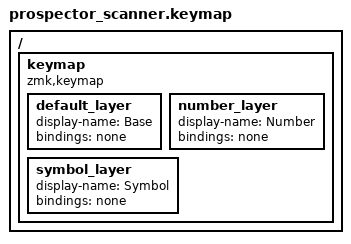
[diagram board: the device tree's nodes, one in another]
/*
 * Copyright (c) 2024 The ZMK Contributors
 *
 * SPDX-License-Identifier: MIT
 */

#include <behaviors.dtsi>
#include <dt-bindings/zmk/keys.h>
#include <dt-bindings/zmk/bt.h>
#include <dt-bindings/zmk/outputs.h>

/ {
    keymap {
        compatible = "zmk,keymap";

        // Default layer - scanner has no physical keys
        default_layer {
            display-name = "Base";
            bindings = <&none>;
        };

        number_layer {
            display-name = "Number";
            bindings = <&none>;
        };

        symbol_layer {
            display-name = "Symbol";
            bindings = <&none>;
        };
    };
};

// Touch input - direct CST816S handling for raw coordinate debugging
